# S32K116_M0P register map
Vendor: NXP Semiconductors; File version: 1.1
CPU: CM0PLUS r0p0, little endian, MPU, FPU, VTOR, 4 interrupt priority bits
Registers are 32-bit, read-write, reset 0x0 unless marked. A register's access mark holds for its fields unless they carry their own. Offsets are from the block's base; [hi:lo] are bit positions; {n}, {i} and the like mark numbered series.

## FTFC
Base 0x40020000
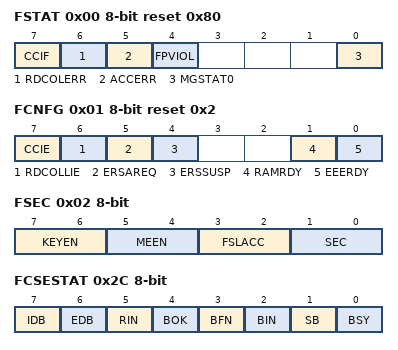
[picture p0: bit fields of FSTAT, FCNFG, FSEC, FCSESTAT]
0x00 FSTAT 8-bit reset 0x80 — Flash Status Register
  [7] CCIF write-1-clears — Command Complete Interrupt Flag
    0=FTFC command or emulated EEPROM file system operation in progress; 1=FTFC command or emulated EEPROM file system operation has completed
  [6] RDCOLERR write-1-clears — FTFC Read Collision Error Flag
    0=No collision error detected; 1=Collision error detected
  [5] ACCERR write-1-clears — Flash Access Error Flag
    0=No access error detected; 1=Access error detected
  [4] FPVIOL write-1-clears — Flash Protection Violation Flag
    0=No protection violation detected; 1=Protection violation detected
  [0] MGSTAT0 ro — Memory Controller Command Completion Status Flag
0x01 FCNFG 8-bit reset 0x2 — Flash Configuration Register
  [7] CCIE — Command Complete Interrupt Enable
    0=Command complete interrupt disabled; 1=Command complete interrupt enabled. An interrupt request is generated whenever the FSTAT[CCIF] flag is set.
  [6] RDCOLLIE — Read Collision Error Interrupt Enable
    0=Read collision error interrupt disabled; 1=Read collision error interrupt enabled. An interrupt request is generated whenever an FTFC read collision error is detected (see the description of FSTAT[RDCOLERR]).
  [5] ERSAREQ ro — Erase All Request
    0=No request or request complete; 1=Request to: (1) run the Erase All Blocks command, (2) verify the erased state, (3) program the security byte in the Flash Configuration Field to the unsecure state, and (4) release MCU security by setting the FSEC[SEC] field to the unsecure state
  [4] ERSSUSP — Erase Suspend
    0=No suspend requested; 1=Suspend the current Erase Flash Sector command execution
  [1] RAMRDY ro — RAM Ready
    0=FlexRAM is not available for traditional RAM access; 1=FlexRAM is available as traditional RAM only; writes to the FlexRAM do not trigger EEPROM operations
  [0] EEERDY ro
    0=FlexRAM is not available for emulated EEPROM operation; 1=FlexRAM is available for EEPROM operations where: (1) reads from the FlexRAM return data previously written to the FlexRAM in emulated EEPROM mode and (2) writes launch an EEPROM operation to store the written data in the FlexRAM and EEPROM backup
0x02 FSEC 8-bit ro reset not defined — Flash Security Register
  [7:6] KEYEN — Backdoor Key Security Enable
    0=Backdoor key access disabled; 1=Backdoor key access disabled (preferred KEYEN state to disable backdoor key access); 2=Backdoor key access enabled; 3=Backdoor key access disabled
  [5:4] MEEN — Mass Erase Enable Bits
    0=Mass erase is enabled; 1=Mass erase is enabled; 2=Mass erase is disabled; 3=Mass erase is enabled
  [3:2] FSLACC — Factory Failure Analysis Access Code
    0=Factory access granted; 1=Factory access denied; 2=Factory access denied; 3=Factory access granted
  [1:0] SEC — Flash Security
    0=MCU security status is secure; 1=MCU security status is secure; 2=MCU security status is unsecure (The standard shipping condition of the FTFC is unsecure.); 3=MCU security status is secure
0x03 FOPT 8-bit ro reset not defined — Flash Option Register
  [7:0] OPT — Nonvolatile Option
0x04 FCCOB{x} (x=3,2,1,0,7,6,5,4,B,A,9,8; step 0x1) 8-bit — Flash Common Command Object Registers
  [7:0] CCOBn
0x10 FPROT{x} (x=3,2,1,0; step 0x1) 8-bit reset not defined — Program Flash Protection Registers
  [7:0] PROT — Program Flash Region Protect
0x16 FEPROT 8-bit reset not defined — EEPROM Protection Register
  [7:0] EPROT — EEPROM Region Protect
    0=EEPROM region is protected; 1=EEPROM region is not protected
0x17 FDPROT 8-bit reset not defined — Data Flash Protection Register
  [7:0] DPROT — Data Flash Region Protect
    0=Data Flash region is protected; 1=Data Flash region is not protected
0x2C FCSESTAT 8-bit ro — Flash CSEc Status Register
  [7] IDB — Internal Debug
    0=Internal debug functions are disabled; 1=Internal debugger functions are enabled
  [6] EDB — External Debug
    0=External debugger not attached; 1=External debugger is attached
  [5] RIN — Random Number Generator Initialized
    0=Random number generator is not initialized; 1=Random number generator is initialized
  [4] BOK — Secure Boot OK
    0=Secure boot is not complete, or secure boot failure; 1=Secure boot was successful
  [3] BFN — Secure Boot Finished
    0=Secure Boot is not finished; 1=Secure Boot has finished
  [2] BIN — Secure Boot Initialization
    0=Secure boot personalization not completed; 1=Secure boot personalization has completed
  [1] SB — Secure Boot
    0=Secure boot not activated; 1=Secure boot is activated
  [0] BSY — Busy
    0=CSEc command processing has completed; 1=CSEc command processing is in progress
0x2E FERSTAT 8-bit write-1-clears — Flash Error Status Register
  [1] DFDIF write-1-clears — Double Bit Fault Detect Interrupt Flag
    0=Double bit fault not detected during a valid flash read access from the platform flash controller; 1=Double bit fault detected (or FERCNFG[FDFD] is set) during a valid flash read access from the platform flash controller
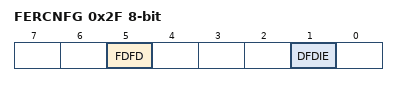
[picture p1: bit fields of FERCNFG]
0x2F FERCNFG 8-bit — Flash Error Configuration Register
  [5] FDFD — Force Double Bit Fault Detect
    0=FERSTAT[DFDIF] sets only if a double bit fault is detected during read access from the platform flash controller; 1=FERSTAT[DFDIF] sets during any valid flash read access from the platform flash controller. An interrupt request is generated if the DFDIE bit is set.
  [1] DFDIE — Double Bit Fault Detect Interrupt Enable
    0=Double bit fault detect interrupt disabled; 1=Double bit fault detect interrupt enabled. An interrupt request is generated whenever the FERSTAT[DFDIF] flag is set.

## Notices in the file
Copyright 2016-2022 NXP
NXP Confidential. This software is owned or controlled by NXP and may only be
used strictly in accordance with the applicable license terms. By expressly
accepting such terms or by downloading, installing, activating and/or otherwise
using the software, you are agreeing that you have read, and that you agree to
comply with and are bound by, such license terms. If you do not agree to be
bound by the applicable license terms, then you may not retain, install,
activate or otherwise use the software. The production use license in
Section 2.3 is expressly granted for this software.
